# MM32F3270 register map
File version: 3.01
CPU: CM3 r2p1, selectable endian, MPU, no FPU, 3 interrupt priority bits
Registers are 32-bit, read-write, reset 0x0 unless marked. A register's access mark holds for its fields unless they carry their own. Offsets are from the block's base; [hi:lo] are bit positions.

## Ethernet_DMA — Ethernet: DMA controller operation
Base 0x40029000
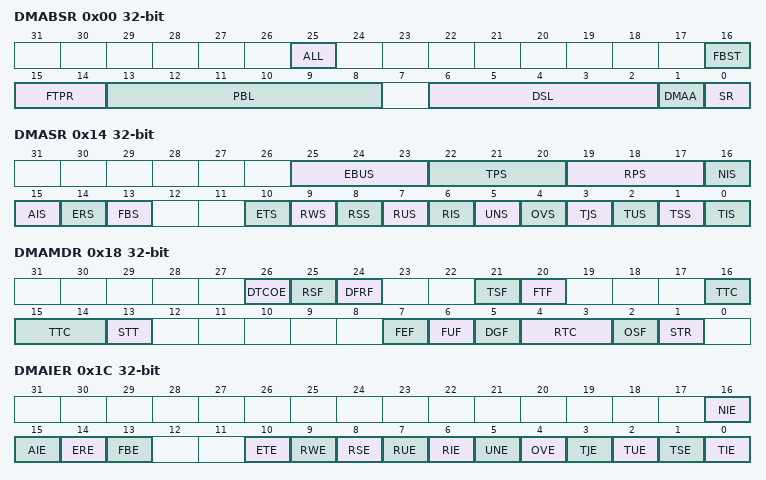
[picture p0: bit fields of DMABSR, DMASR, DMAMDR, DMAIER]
0x00 DMABSR — Ethernet DMA bus mode register
  [25] ALL — *D25
  [16] FBST — Fixed burst
  [15:14] FTPR — Rx Tx priority ratio
  [13:8] PBL — Programmable burst length
  [6:2] DSL — Descriptor skip length
  [1] DMAA — DMA Arbitration
  [0] SR — Software reset
0x04 DMATXPDR — Ethernet DMA transmit poll demand register
  [31:0] TXPD — Transmit poll demand
0x08 DMARXPDR — EHERNET DMA receive poll demand register
  [31:0] RXPD — Receive poll demand
0x0C DMATXDSAR — Ethernet DMA receive descriptor list address register
  [31:0] TXDSA — Start of receive list
0x10 DMATDLAR — Ethernet DMA transmit descriptor list address register
  [31:0] STL — Start of transmit list
0x14 DMASR access per field — Ethernet DMA status register
  [25:23] EBUS ro — Error Bits Status
  [22:20] TPS ro — Transmit Process State
  [19:17] RPS ro — Receive Process State
  [16] NIS rw write-1-clears — Normal Interrupt Summary
  [15] AIS rw write-1-clears — Abnormal Interrupt Summary
  [14] ERS rw write-1-clears — Early Receive Interrupt Status
  [13] FBS rw write-1-clears — Fatal Bus Error Interrupt Status
  [10] ETS rw write-1-clears — Early Transmit Interrupt Status
  [9] RWS rw write-1-clears — Receive Watchdog Timeout Status
  [8] RSS rw write-1-clears — Receive Process Stopped Status
  [7] RUS rw write-1-clears — Receive Buffer Unavailable Status
  [6] RIS rw write-1-clears — Receive Status
  [5] UNS rw write-1-clears — Transmit Underflow Status
  [4] OVS rw write-1-clears — Receive Overflow Status
  [3] TJS rw write-1-clears — Transmit Jabber Timeout Status
  [2] TUS rw write-1-clears — Transmit Buffer Unavailable Status
  [1] TSS rw write-1-clears — Transmit Process Stopped Status
  [0] TIS rw write-1-clears — Transmit Interrupt Status
0x18 DMAMDR — Ethernet DMA operation mode register
  [26] DTCOE — If there are only errors detected by the receive checksum offload engine in the received frame, the kernel will not discard the frame
  [25] RSF — After the RxFIFO writes a complete frame, it executes the read action while ignoring the RTC bit
  [24] DFRF — When this bit is set to 1, RxDMA will not refresh any frame because the receive descriptor/buffer is unavailable, please refer to the section "Receiving Process Suspended"
  [21] TSF — Transmit Store and Forward
  [20] FTF — Flush Transmit FIFO
  [16:14] TTC — Transmit threshold control
  [13] STT — Start/stop transmission
  [7] FEF — For Error Frames
  [6] FUF — Forward undersized goodframes
  [5] DGF — RxFIFO discards jumbo frames
  [4:3] RTC — Receive threshold control
  [2] OSF — Operate on second frame
  [1] STR — Start/Stop Receive
0x1C DMAIER — Ethernet DMA interrupt enable register
  [16] NIE — Normal Interrupt Summary Enable
  [15] AIE — Abnormal Interrupt Summary Enable
  [14] ERE — Early Receive Interrupt Enable
  [13] FBE — Fatal Bus Error Interrupt Enable
  [10] ETE — Early Transmit Interrupt
  [9] RWE — Receive Watchdog Timeout Interrupt En-able
  [8] RSE — Receive Process Stopped Inter-rupt Enable
  [7] RUE — Receive Buffer Unavailable In-terrupt Enable
  [6] RIE — Receive Interrupt Enable
  [5] UNE — Underflow Interrupt Enable
  [4] OVE — Overflow Interrupt Enable
  [3] TJE — Transmit jabber timeout interruptenable
  [2] TUE — Transmit buffer unavailable in-terrupt enable
  [1] TSE — Transmit process stopped inter-rupt enable
  [0] TIE — Transmit interrupt enable
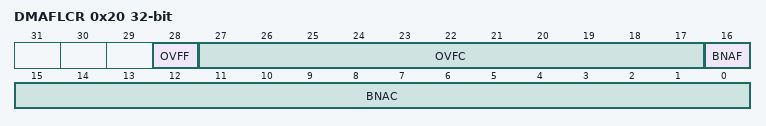
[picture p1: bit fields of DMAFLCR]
0x20 DMAFLCR ro read-clears — Ethernet DMA missed frame and buffer overflow counter register
  [28] OVFF — Overflow bit for FIFO overflowcounter
  [27:17] OVFC — Missed frames by the application
  [16] BNAF — Overflow bit for missed framecounter
  [15:0] BNAC — Missed frames by the controller
0x24 DMAWDTR ro read-clears — Ethernet Watchdog register
  [7:0] RIWT — *D0
0x48 DMACUTTXDSAR ro — Ethernet DMA current host transmit descriptor register
  [31:0] CUTTXDSA — Host Receive Descriptor AddressPointer
0x50 DMACUTTXBUFR ro — Ethernet DMA current host transmit buffer address register
  [31:0] CUTTXBUF — Host Transmit Buffer Address Pointer
0x54 DMACUTRXBUFR ro — Ethernet DMA current host receive buffer address register
  [31:0] CUTRXBUF — Host Receive Buffer Address Pointer
